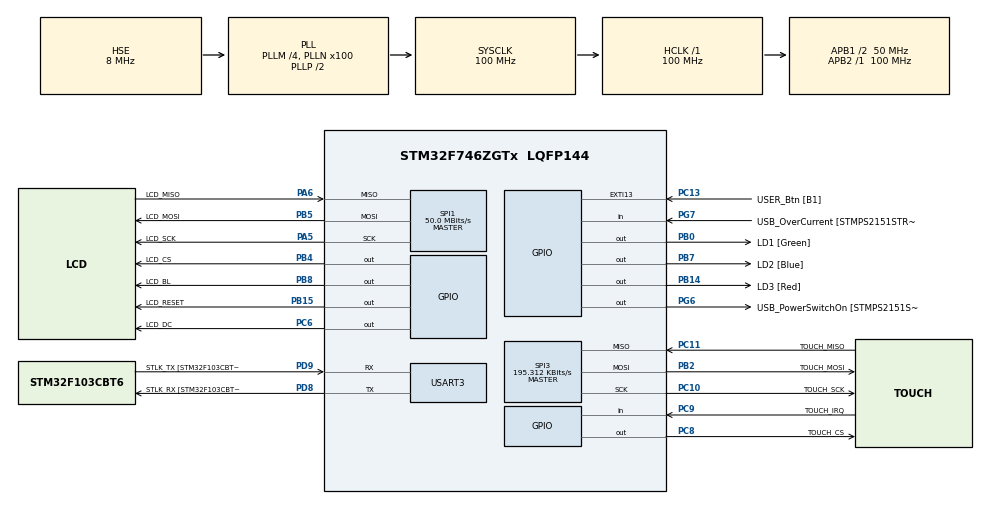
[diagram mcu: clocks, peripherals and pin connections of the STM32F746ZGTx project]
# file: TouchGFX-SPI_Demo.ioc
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Dma.Request0=SPI1_TX
Dma.SPI1_TX.0.Direction=DMA_MEMORY_TO_PERIPH
Dma.SPI1_TX.0.FIFOMode=DMA_FIFOMODE_ENABLE
Dma.SPI1_TX.0.FIFOThreshold=DMA_FIFO_THRESHOLD_FULL
Dma.SPI1_TX.0.Instance=DMA2_Stream3
Dma.SPI1_TX.0.MemBurst=DMA_MBURST_SINGLE
Dma.SPI1_TX.0.MemDataAlignment=DMA_MDATAALIGN_BYTE
Dma.SPI1_TX.0.MemInc=DMA_MINC_ENABLE
Dma.SPI1_TX.0.Mode=DMA_NORMAL
Dma.SPI1_TX.0.PeriphBurst=DMA_PBURST_SINGLE
Dma.SPI1_TX.0.PeriphDataAlignment=DMA_PDATAALIGN_BYTE
Dma.SPI1_TX.0.PeriphInc=DMA_PINC_DISABLE
Dma.SPI1_TX.0.Priority=DMA_PRIORITY_LOW
Mcu.Family=STM32F7
Mcu.Name=STM32F746ZGTx
Mcu.Package=LQFP144
NVIC.DMA2_Stream3_IRQn=true\:1\:0\:true\:false\:true\:false\:true
NVIC.PriorityGroup=NVIC_PRIORITYGROUP_4
NVIC.SPI1_IRQn=true\:2\:0\:true\:false\:true\:true\:true
NVIC.SPI3_IRQn=true\:3\:0\:true\:false\:true\:true\:true
NVIC.TIM8_UP_TIM13_IRQn=true\:5\:0\:true\:false\:true\:true\:true
PA1.GPIO_Label=RMII_REF_CLK [LAN8742A-CZ-TR_REFCLK0]
PA1.Signal=ETH_REF_CLK
PA10.GPIO_Label=USB_ID
PA10.Signal=USB_OTG_FS_ID
PA11.GPIO_Label=USB_DM
PA11.Signal=USB_OTG_FS_DM
PA12.GPIO_Label=USB_DP
PA12.Signal=USB_OTG_FS_DP
PA13.GPIO_Label=TMS
PA13.Mode=Serial_Wire
PA13.Signal=SYS_JTMS-SWDIO
PA14.GPIO_Label=TCK
PA14.Mode=Serial_Wire
PA14.Signal=SYS_JTCK-SWCLK
PA2.GPIO_Label=RMII_MDIO [LAN8742A-CZ-TR_MDIO]
PA2.Signal=ETH_MDIO
PA5.GPIO_Label=LCD_SCK
PA5.Mode=Full_Duplex_Master
PA5.Signal=SPI1_SCK
PA6.GPIO_Label=LCD_MISO
PA6.Mode=Full_Duplex_Master
PA6.Signal=SPI1_MISO
PA7.GPIO_Label=RMII_CRS_DV [LAN8742A-CZ-TR_CRS_DV]
PA7.Signal=ETH_CRS_DV
PA8.GPIO_Label=USB_SOF [TP1]
PA8.Signal=USB_OTG_FS_SOF
PA9.GPIO_Label=USB_VBUS
PA9.Signal=USB_OTG_FS_VBUS
PB0.GPIO_Label=LD1 [Green]
PB0.Signal=GPIO_Output
PB13.GPIO_Label=RMII_TXD1 [LAN8742A-CZ-TR_TXD1]
PB13.Signal=ETH_TXD1
PB14.GPIO_Label=LD3 [Red]
PB14.Signal=GPIO_Output
PB15.GPIO_Label=LCD_RESET
PB15.PinState=GPIO_PIN_SET
PB15.Signal=GPIO_Output
PB2.GPIO_Label=TOUCH_MOSI
PB2.Mode=Full_Duplex_Master
PB2.Signal=SPI3_MOSI
PB3.GPIO_Label=SW0
PB3.Signal=SYS_JTDO-SWO
PB4.GPIO_Label=LCD_CS
PB4.PinState=GPIO_PIN_SET
PB4.Signal=GPIO_Output
PB5.GPIO_Label=LCD_MOSI
PB5.Mode=Full_Duplex_Master
PB5.Signal=SPI1_MOSI
PB7.GPIO_Label=LD2 [Blue]
PB7.Signal=GPIO_Output
PB8.GPIO_Label=LCD_BL
PB8.PinState=GPIO_PIN_SET
PB8.Signal=GPIO_Output
PC1.GPIO_Label=RMII_MDC [LAN8742A-CZ-TR_MDC]
PC1.Signal=ETH_MDC
PC10.GPIO_Label=TOUCH_SCK
PC10.Mode=Full_Duplex_Master
PC10.Signal=SPI3_SCK
PC11.GPIO_Label=TOUCH_MISO
PC11.Mode=Full_Duplex_Master
PC11.Signal=SPI3_MISO
PC13.GPIO_Label=USER_Btn [B1]
PC13.Signal=GPXTI13
PC14/OSC32_IN.Mode=LSE-External-Oscillator
PC14/OSC32_IN.Signal=RCC_OSC32_IN
PC15/OSC32_OUT.Mode=LSE-External-Oscillator
PC15/OSC32_OUT.Signal=RCC_OSC32_OUT
PC4.GPIO_Label=RMII_RXD0 [LAN8742A-CZ-TR_RXD0]
PC4.Signal=ETH_RXD0
PC5.GPIO_Label=RMII_RXD1 [LAN8742A-CZ-TR_RXD1]
PC5.Signal=ETH_RXD1
PC6.GPIO_Label=LCD_DC
PC6.PinState=GPIO_PIN_SET
PC6.Signal=GPIO_Output
PC8.GPIO_Label=TOUCH_CS
PC8.PinState=GPIO_PIN_SET
PC8.Signal=GPIO_Output
PC9.GPIO_Label=TOUCH_IRQ
PC9.Signal=GPIO_Input
PD8.GPIO_Label=STLK_RX [STM32F103CBT6_PA3]
PD8.Mode=Asynchronous
PD8.Signal=USART3_TX
PD9.GPIO_Label=STLK_TX [STM32F103CBT6_PA2]
PD9.Mode=Asynchronous
PD9.Signal=USART3_RX
PG11.GPIO_Label=RMII_TX_EN [LAN8742A-CZ-TR_TXEN]
PG11.Signal=ETH_TX_EN
PG13.GPIO_Label=RMII_TXD0 [LAN8742A-CZ-TR_TXD0]
PG13.Signal=ETH_TXD0
PG6.GPIO_Label=USB_PowerSwitchOn [STMPS2151STR_EN]
PG6.Signal=GPIO_Output
PG7.GPIO_Label=USB_OverCurrent [STMPS2151STR_FAULT]
PG7.Signal=GPIO_Input
PH0/OSC_IN.GPIO_Label=MCO [STM32F103CBT6_PA8]
PH0/OSC_IN.Mode=HSE-External-Clock-Source
PH0/OSC_IN.Signal=RCC_OSC_IN
PH1/OSC_OUT.Mode=HSE-External-Clock-Source
PH1/OSC_OUT.Signal=RCC_OSC_OUT
ProjectManager.HeapSize=0x200
ProjectManager.StackSize=0x400
ProjectManager.TargetToolchain=STM32CubeIDE
RCC.48MHZClocksFreq_Value=24000000
RCC.AHBFreq_Value=100000000
RCC.APB1CLKDivider=RCC_HCLK_DIV2
RCC.APB1Freq_Value=50000000
RCC.APB1TimFreq_Value=100000000
RCC.APB2Freq_Value=100000000
RCC.APB2TimFreq_Value=100000000
RCC.CortexFreq_Value=100000000
RCC.HCLKFreq_Value=100000000
RCC.HSE_VALUE=8000000
RCC.HSI_VALUE=16000000
RCC.PLLM=4
RCC.PLLMUL=RCC_PLL_MUL9
RCC.PLLN=100
RCC.PLLQ=3
RCC.PLLSourceVirtual=RCC_PLLSOURCE_HSE
RCC.PRESCALERUSB=RCC_USBCLKSOURCE_PLL_DIV1_5
RCC.SYSCLKFreq_VALUE=100000000
RCC.SYSCLKSource=RCC_SYSCLKSOURCE_PLLCLK
RCC.SYSCLKSourceVirtual=RCC_SYSCLKSOURCE_PLLCLK
RCC.USBFreq_Value=66666666.666666664
RCC.VCOOutputFreq_Value=200000000
SPI1.CalculateBaudRate=50.0 MBits/s
SPI1.DataSize=SPI_DATASIZE_8BIT
SPI1.Direction=SPI_DIRECTION_2LINES
SPI1.Mode=SPI_MODE_MASTER
SPI1.VirtualType=VM_MASTER
SPI3.BaudRatePrescaler=SPI_BAUDRATEPRESCALER_256
SPI3.CalculateBaudRate=195.312 KBits/s
SPI3.DataSize=SPI_DATASIZE_8BIT
SPI3.Direction=SPI_DIRECTION_2LINES
SPI3.Mode=SPI_MODE_MASTER
SPI3.VirtualType=VM_MASTER
STMicroelectronics.X-CUBE-TOUCHGFX.4.13.0.ApplicationCcGraphicsJjApplication=TouchGFXOoGenerator
STMicroelectronics.X-CUBE-TOUCHGFX.4.13.0.tgfx_custom_height=240
STMicroelectronics.X-CUBE-TOUCHGFX.4.13.0.tgfx_custom_width=320
TIM13.Period=15
TIM13.Prescaler=49999
USART3.VirtualMode-Asynchronous=VM_ASYNC
VP_CRC_VS_CRC.Mode=CRC_Activate
VP_STMicroelectronics.X-CUBE-TOUCHGFX_VS_GraphicsJjApplication_4.13.0.Mode=GraphicsJjApplication
VP_TIM13_VS_ClockSourceINT.Mode=Enable_Timer
board=NUCLEO-F746ZG

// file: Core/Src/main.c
/* USER CODE BEGIN Header */
/**
  ******************************************************************************
  * @file           : main.c
  * @brief          : Main program body
  ******************************************************************************
  * @attention
  *
  * <h2><center>&copy; Copyright (c) 2020 STMicroelectronics.
  * All rights reserved.</center></h2>
  *
  * This software component is licensed by ST under Ultimate Liberty license
  * SLA0044, the "License"; You may not use this file except in compliance with
  * the License. You may obtain a copy of the License at:
  *                             www.st.com/SLA0044
  *
  ******************************************************************************
  */
/* USER CODE END Header */

#include "main.h"
#include "app_touchgfx.h"

/* USER CODE BEGIN Includes */
#include "ili9341.h"
/* USER CODE END Includes */

CRC_HandleTypeDef hcrc;

SPI_HandleTypeDef hspi1;
SPI_HandleTypeDef hspi3;
DMA_HandleTypeDef hdma_spi1_tx;

TIM_HandleTypeDef htim13;

UART_HandleTypeDef huart3;

void SystemClock_Config(void);
static void MX_GPIO_Init(void);
static void MX_DMA_Init(void);
static void MX_USART3_UART_Init(void);
static void MX_CRC_Init(void);
static void MX_SPI1_Init(void);
static void MX_SPI3_Init(void);
static void MX_TIM13_Init(void);

int main(void)
{

  /* MCU Configuration--------------------------------------------------------*/

  /* Reset of all peripherals, Initializes the Flash interface and the Systick. */
  HAL_Init();

  /* Configure the system clock */
  SystemClock_Config();

  /* Initialize all configured peripherals */
  MX_GPIO_Init();
  MX_DMA_Init();
  MX_USART3_UART_Init();
  MX_CRC_Init();
  MX_SPI1_Init();
  MX_SPI3_Init();
  MX_TIM13_Init();
  MX_TouchGFX_Init();
  /* USER CODE BEGIN 2 */
  ILI9341_Init();
  /* USER CODE END 2 */

  /* Infinite loop */
  while (1)
  {

  MX_TouchGFX_Process();
  }
}

void SystemClock_Config(void)
{
  RCC_OscInitTypeDef RCC_OscInitStruct = {0};
  RCC_ClkInitTypeDef RCC_ClkInitStruct = {0};
  RCC_PeriphCLKInitTypeDef PeriphClkInitStruct = {0};

  /** Configure LSE Drive Capability
  */
  HAL_PWR_EnableBkUpAccess();
  /** Configure the main internal regulator output voltage
  */
  __HAL_RCC_PWR_CLK_ENABLE();
  __HAL_PWR_VOLTAGESCALING_CONFIG(PWR_REGULATOR_VOLTAGE_SCALE3);
  /** Initializes the CPU, AHB and APB busses clocks
  */
  RCC_OscInitStruct.OscillatorType = RCC_OSCILLATORTYPE_HSE;
  RCC_OscInitStruct.HSEState = RCC_HSE_BYPASS;
  RCC_OscInitStruct.PLL.PLLState = RCC_PLL_ON;
  RCC_OscInitStruct.PLL.PLLSource = RCC_PLLSOURCE_HSE;
  RCC_OscInitStruct.PLL.PLLM = 4;
  RCC_OscInitStruct.PLL.PLLN = 100;
  RCC_OscInitStruct.PLL.PLLP = RCC_PLLP_DIV2;
  RCC_OscInitStruct.PLL.PLLQ = 3;
  if (HAL_RCC_OscConfig(&RCC_OscInitStruct) != HAL_OK)
  {
    Error_Handler();
  }
  /** Activate the Over-Drive mode
  */
  if (HAL_PWREx_EnableOverDrive() != HAL_OK)
  {
    Error_Handler();
  }
  /** Initializes the CPU, AHB and APB busses clocks
  */
  RCC_ClkInitStruct.ClockType = RCC_CLOCKTYPE_HCLK|RCC_CLOCKTYPE_SYSCLK
                              |RCC_CLOCKTYPE_PCLK1|RCC_CLOCKTYPE_PCLK2;
  RCC_ClkInitStruct.SYSCLKSource = RCC_SYSCLKSOURCE_PLLCLK;
  RCC_ClkInitStruct.AHBCLKDivider = RCC_SYSCLK_DIV1;
  RCC_ClkInitStruct.APB1CLKDivider = RCC_HCLK_DIV2;
  RCC_ClkInitStruct.APB2CLKDivider = RCC_HCLK_DIV1;

  if (HAL_RCC_ClockConfig(&RCC_ClkInitStruct, FLASH_LATENCY_3) != HAL_OK)
  {
    Error_Handler();
  }
  PeriphClkInitStruct.PeriphClockSelection = RCC_PERIPHCLK_USART3;
  PeriphClkInitStruct.Usart3ClockSelection = RCC_USART3CLKSOURCE_PCLK1;
  if (HAL_RCCEx_PeriphCLKConfig(&PeriphClkInitStruct) != HAL_OK)
  {
    Error_Handler();
  }
}

static void MX_CRC_Init(void)
{

  hcrc.Instance = CRC;
  hcrc.Init.DefaultPolynomialUse = DEFAULT_POLYNOMIAL_ENABLE;
  hcrc.Init.DefaultInitValueUse = DEFAULT_INIT_VALUE_ENABLE;
  hcrc.Init.InputDataInversionMode = CRC_INPUTDATA_INVERSION_NONE;
  hcrc.Init.OutputDataInversionMode = CRC_OUTPUTDATA_INVERSION_DISABLE;
  hcrc.InputDataFormat = CRC_INPUTDATA_FORMAT_BYTES;
  if (HAL_CRC_Init(&hcrc) != HAL_OK)
  {
    Error_Handler();
  }

}

static void MX_SPI1_Init(void)
{

  /* SPI1 parameter configuration*/
  hspi1.Instance = SPI1;
  hspi1.Init.Mode = SPI_MODE_MASTER;
  hspi1.Init.Direction = SPI_DIRECTION_2LINES;
  hspi1.Init.DataSize = SPI_DATASIZE_8BIT;
  hspi1.Init.CLKPolarity = SPI_POLARITY_LOW;
  hspi1.Init.CLKPhase = SPI_PHASE_1EDGE;
  hspi1.Init.NSS = SPI_NSS_SOFT;
  hspi1.Init.BaudRatePrescaler = SPI_BAUDRATEPRESCALER_2;
  hspi1.Init.FirstBit = SPI_FIRSTBIT_MSB;
  hspi1.Init.TIMode = SPI_TIMODE_DISABLE;
  hspi1.Init.CRCCalculation = SPI_CRCCALCULATION_DISABLE;
  hspi1.Init.CRCPolynomial = 7;
  hspi1.Init.CRCLength = SPI_CRC_LENGTH_DATASIZE;
  hspi1.Init.NSSPMode = SPI_NSS_PULSE_ENABLE;
  if (HAL_SPI_Init(&hspi1) != HAL_OK)
  {
    Error_Handler();
  }

}

static void MX_SPI3_Init(void)
{

  /* SPI3 parameter configuration*/
  hspi3.Instance = SPI3;
  hspi3.Init.Mode = SPI_MODE_MASTER;
  hspi3.Init.Direction = SPI_DIRECTION_2LINES;
  hspi3.Init.DataSize = SPI_DATASIZE_8BIT;
  hspi3.Init.CLKPolarity = SPI_POLARITY_LOW;
  hspi3.Init.CLKPhase = SPI_PHASE_1EDGE;
  hspi3.Init.NSS = SPI_NSS_SOFT;
  hspi3.Init.BaudRatePrescaler = SPI_BAUDRATEPRESCALER_256;
  hspi3.Init.FirstBit = SPI_FIRSTBIT_MSB;
  hspi3.Init.TIMode = SPI_TIMODE_DISABLE;
  hspi3.Init.CRCCalculation = SPI_CRCCALCULATION_DISABLE;
  hspi3.Init.CRCPolynomial = 7;
  hspi3.Init.CRCLength = SPI_CRC_LENGTH_DATASIZE;
  hspi3.Init.NSSPMode = SPI_NSS_PULSE_ENABLE;
  if (HAL_SPI_Init(&hspi3) != HAL_OK)
  {
    Error_Handler();
  }

}

static void MX_TIM13_Init(void)
{

  htim13.Instance = TIM13;
  htim13.Init.Prescaler = 49999;
  htim13.Init.CounterMode = TIM_COUNTERMODE_UP;
  htim13.Init.Period = 15;
  htim13.Init.ClockDivision = TIM_CLOCKDIVISION_DIV1;
  htim13.Init.AutoReloadPreload = TIM_AUTORELOAD_PRELOAD_DISABLE;
  if (HAL_TIM_Base_Init(&htim13) != HAL_OK)
  {
    Error_Handler();
  }
  /* USER CODE BEGIN TIM13_Init 2 */
  HAL_TIM_Base_Start_IT(&htim13);

  /* USER CODE END TIM13_Init 2 */

}

static void MX_USART3_UART_Init(void)
{

  huart3.Instance = USART3;
  huart3.Init.BaudRate = 115200;
  huart3.Init.WordLength = UART_WORDLENGTH_8B;
  huart3.Init.StopBits = UART_STOPBITS_1;
  huart3.Init.Parity = UART_PARITY_NONE;
  huart3.Init.Mode = UART_MODE_TX_RX;
  huart3.Init.HwFlowCtl = UART_HWCONTROL_NONE;
  huart3.Init.OverSampling = UART_OVERSAMPLING_16;
  huart3.Init.OneBitSampling = UART_ONE_BIT_SAMPLE_DISABLE;
  huart3.AdvancedInit.AdvFeatureInit = UART_ADVFEATURE_NO_INIT;
  if (HAL_UART_Init(&huart3) != HAL_OK)
  {
    Error_Handler();
  }

}

static void MX_DMA_Init(void)
{

  /* DMA controller clock enable */
  __HAL_RCC_DMA2_CLK_ENABLE();

  /* DMA interrupt init */
  /* DMA2_Stream3_IRQn interrupt configuration */
  HAL_NVIC_SetPriority(DMA2_Stream3_IRQn, 1, 0);
  HAL_NVIC_EnableIRQ(DMA2_Stream3_IRQn);

}

static void MX_GPIO_Init(void)
{
  GPIO_InitTypeDef GPIO_InitStruct = {0};

  /* GPIO Ports Clock Enable */
  __HAL_RCC_GPIOC_CLK_ENABLE();
  __HAL_RCC_GPIOH_CLK_ENABLE();
  __HAL_RCC_GPIOA_CLK_ENABLE();
  __HAL_RCC_GPIOB_CLK_ENABLE();
  __HAL_RCC_GPIOD_CLK_ENABLE();
  __HAL_RCC_GPIOG_CLK_ENABLE();

  /*Configure GPIO pin Output Level */
  HAL_GPIO_WritePin(GPIOB, LD1_Pin|LD3_Pin|LD2_Pin, GPIO_PIN_RESET);

  /*Configure GPIO pin Output Level */
  HAL_GPIO_WritePin(GPIOB, LCD_RESET_Pin|LCD_CS_Pin|LCD_BL_Pin, GPIO_PIN_SET);

  /*Configure GPIO pin Output Level */
  HAL_GPIO_WritePin(USB_PowerSwitchOn_GPIO_Port, USB_PowerSwitchOn_Pin, GPIO_PIN_RESET);

  /*Configure GPIO pin Output Level */
  HAL_GPIO_WritePin(GPIOC, LCD_DC_Pin|TOUCH_CS_Pin, GPIO_PIN_SET);

  /*Configure GPIO pin : USER_Btn_Pin */
  GPIO_InitStruct.Pin = USER_Btn_Pin;
  GPIO_InitStruct.Mode = GPIO_MODE_IT_RISING;
  GPIO_InitStruct.Pull = GPIO_NOPULL;
  HAL_GPIO_Init(USER_Btn_GPIO_Port, &GPIO_InitStruct);

  /*Configure GPIO pins : RMII_MDC_Pin RMII_RXD0_Pin RMII_RXD1_Pin */
  GPIO_InitStruct.Pin = RMII_MDC_Pin|RMII_RXD0_Pin|RMII_RXD1_Pin;
  GPIO_InitStruct.Mode = GPIO_MODE_AF_PP;
  GPIO_InitStruct.Pull = GPIO_NOPULL;
  GPIO_InitStruct.Speed = GPIO_SPEED_FREQ_VERY_HIGH;
  GPIO_InitStruct.Alternate = GPIO_AF11_ETH;
  HAL_GPIO_Init(GPIOC, &GPIO_InitStruct);

  /*Configure GPIO pins : RMII_REF_CLK_Pin RMII_MDIO_Pin RMII_CRS_DV_Pin */
  GPIO_InitStruct.Pin = RMII_REF_CLK_Pin|RMII_MDIO_Pin|RMII_CRS_DV_Pin;
  GPIO_InitStruct.Mode = GPIO_MODE_AF_PP;
  GPIO_InitStruct.Pull = GPIO_NOPULL;
  GPIO_InitStruct.Speed = GPIO_SPEED_FREQ_VERY_HIGH;
  GPIO_InitStruct.Alternate = GPIO_AF11_ETH;
  HAL_GPIO_Init(GPIOA, &GPIO_InitStruct);

  /*Configure GPIO pins : LD1_Pin LD3_Pin LCD_RESET_Pin LCD_CS_Pin
                           LD2_Pin LCD_BL_Pin */
  GPIO_InitStruct.Pin = LD1_Pin|LD3_Pin|LCD_RESET_Pin|LCD_CS_Pin
                          |LD2_Pin|LCD_BL_Pin;
  GPIO_InitStruct.Mode = GPIO_MODE_OUTPUT_PP;
  GPIO_InitStruct.Pull = GPIO_NOPULL;
  GPIO_InitStruct.Speed = GPIO_SPEED_FREQ_LOW;
  HAL_GPIO_Init(GPIOB, &GPIO_InitStruct);

  /*Configure GPIO pin : RMII_TXD1_Pin */
  GPIO_InitStruct.Pin = RMII_TXD1_Pin;
  GPIO_InitStruct.Mode = GPIO_MODE_AF_PP;
  GPIO_InitStruct.Pull = GPIO_NOPULL;
  GPIO_InitStruct.Speed = GPIO_SPEED_FREQ_VERY_HIGH;
  GPIO_InitStruct.Alternate = GPIO_AF11_ETH;
  HAL_GPIO_Init(RMII_TXD1_GPIO_Port, &GPIO_InitStruct);

  /*Configure GPIO pin : USB_PowerSwitchOn_Pin */
  GPIO_InitStruct.Pin = USB_PowerSwitchOn_Pin;
  GPIO_InitStruct.Mode = GPIO_MODE_OUTPUT_PP;
  GPIO_InitStruct.Pull = GPIO_NOPULL;
  GPIO_InitStruct.Speed = GPIO_SPEED_FREQ_LOW;
  HAL_GPIO_Init(USB_PowerSwitchOn_GPIO_Port, &GPIO_InitStruct);

  /*Configure GPIO pin : USB_OverCurrent_Pin */
  GPIO_InitStruct.Pin = USB_OverCurrent_Pin;
  GPIO_InitStruct.Mode = GPIO_MODE_INPUT;
  GPIO_InitStruct.Pull = GPIO_NOPULL;
  HAL_GPIO_Init(USB_OverCurrent_GPIO_Port, &GPIO_InitStruct);

  /*Configure GPIO pins : LCD_DC_Pin TOUCH_CS_Pin */
  GPIO_InitStruct.Pin = LCD_DC_Pin|TOUCH_CS_Pin;
  GPIO_InitStruct.Mode = GPIO_MODE_OUTPUT_PP;
  GPIO_InitStruct.Pull = GPIO_NOPULL;
  GPIO_InitStruct.Speed = GPIO_SPEED_FREQ_LOW;
  HAL_GPIO_Init(GPIOC, &GPIO_InitStruct);

  /*Configure GPIO pin : TOUCH_IRQ_Pin */
  GPIO_InitStruct.Pin = TOUCH_IRQ_Pin;
  GPIO_InitStruct.Mode = GPIO_MODE_INPUT;
  GPIO_InitStruct.Pull = GPIO_NOPULL;
  HAL_GPIO_Init(TOUCH_IRQ_GPIO_Port, &GPIO_InitStruct);

  /*Configure GPIO pins : USB_SOF_Pin USB_ID_Pin USB_DM_Pin USB_DP_Pin */
  GPIO_InitStruct.Pin = USB_SOF_Pin|USB_ID_Pin|USB_DM_Pin|USB_DP_Pin;
  GPIO_InitStruct.Mode = GPIO_MODE_AF_PP;
  GPIO_InitStruct.Pull = GPIO_NOPULL;
  GPIO_InitStruct.Speed = GPIO_SPEED_FREQ_VERY_HIGH;
  GPIO_InitStruct.Alternate = GPIO_AF10_OTG_FS;
  HAL_GPIO_Init(GPIOA, &GPIO_InitStruct);

  /*Configure GPIO pin : USB_VBUS_Pin */
  GPIO_InitStruct.Pin = USB_VBUS_Pin;
  GPIO_InitStruct.Mode = GPIO_MODE_INPUT;
  GPIO_InitStruct.Pull = GPIO_NOPULL;
  HAL_GPIO_Init(USB_VBUS_GPIO_Port, &GPIO_InitStruct);

  /*Configure GPIO pins : RMII_TX_EN_Pin RMII_TXD0_Pin */
  GPIO_InitStruct.Pin = RMII_TX_EN_Pin|RMII_TXD0_Pin;
  GPIO_InitStruct.Mode = GPIO_MODE_AF_PP;
  GPIO_InitStruct.Pull = GPIO_NOPULL;
  GPIO_InitStruct.Speed = GPIO_SPEED_FREQ_VERY_HIGH;
  GPIO_InitStruct.Alternate = GPIO_AF11_ETH;
  HAL_GPIO_Init(GPIOG, &GPIO_InitStruct);

}

/* USER CODE BEGIN 4 */
extern void touchgfx_signalVSyncTimer(void);

void HAL_TIM_PeriodElapsedCallback(TIM_HandleTypeDef *htim)
{
	if (htim->Instance == TIM13) {
		touchgfx_signalVSyncTimer();
	}
	if (htim->Instance == TIM12) {

	}
}
/* USER CODE END 4 */

void Error_Handler(void)
{
}

/************************ (C) COPYRIGHT STMicroelectronics *****END OF FILE****/
